# generated register map
File version: 1.0
Registers are 32-bit, access not given, no defined reset value unless marked. A register's access mark holds for its fields unless they carry their own. Offsets are from the block's base; lines under a group give offsets from that group; [hi:lo] are bit positions; {n}, {i} and the like mark numbered series; 'fields as' and 'values as' point back to an identical list; <NAME> marks a mode.

## Memory map
0x60047000 ieee802154
0x60049000 coex

## ieee802154
Base 0x60047000
0x00 command
  [7:0] opcode
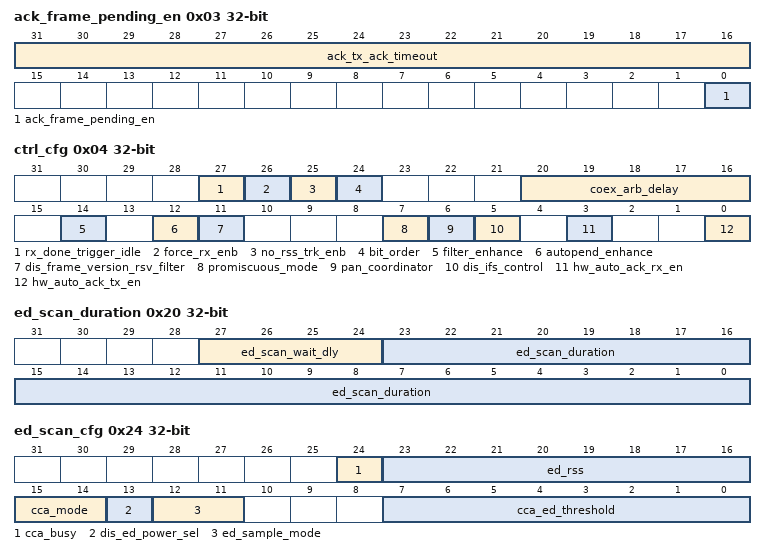
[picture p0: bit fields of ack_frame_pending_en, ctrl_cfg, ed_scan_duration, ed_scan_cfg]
0x03 ack_frame_pending_en
  [31:16] ack_tx_ack_timeout, [0] ack_frame_pending_en
0x04 ctrl_cfg
  [27] rx_done_trigger_idle, [26] force_rx_enb, [25] no_rss_trk_enb, [24] bit_order, [20:16] coex_arb_delay, [14] filter_enhance, [12] autopend_enhance, [11] dis_frame_version_rsv_filter, [7] promiscuous_mode, [6] pan_coordinator, [5] dis_ifs_control, [3] hw_auto_ack_rx_en, [0] hw_auto_ack_tx_en
0x08 short_addr
  [15:0] mac_short_addr
0x0C pan_id
  [15:0] mac_pan_id
0x10 extend_addr0
  [31:0] mac_extend_addr0
0x14 extend_addr1
  [31:0] mac_extend_addr1
0x18 channel
  [6:0] hop
0x1C tx_power
  [3:0] tx_power
0x20 ed_scan_duration
  [27:24] ed_scan_wait_dly, [23:0] ed_scan_duration
0x24 ed_scan_cfg
  [24] cca_busy, [23:16] ed_rss, [15:14] cca_mode, [13] dis_ed_power_sel, [12:11] ed_sample_mode, [7:0] cca_ed_threshold
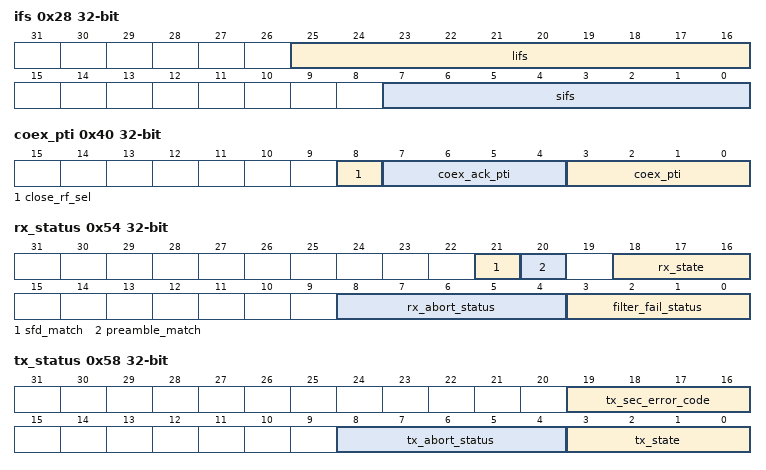
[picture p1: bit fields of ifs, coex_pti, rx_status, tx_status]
0x28 ifs
  [25:16] lifs, [7:0] sifs
0x2C ack_timeout
  [15:0] ack_timeout
0x30 event_en
  [12:0] event_en
0x34 event_status
  [12:0] event_status
0x38 rx_abort_intr_ctrl
  [30:0] rx_abort_intr_ctrl
0x40 coex_pti
  [8] close_rf_sel, [7:4] coex_ack_pti, [3:0] coex_pti
0x44 core_dummy_data
0x48 tx_abort_interrupt_control
  [30:0] tx_abort_interrupt_control
0x54 rx_status
  [21] sfd_match, [20] preamble_match, [18:16] rx_state, [8:4] rx_abort_status, [3:0] filter_fail_status
0x58 tx_status
  [19:16] tx_sec_error_code, [8:4] tx_abort_status, [3:0] tx_state
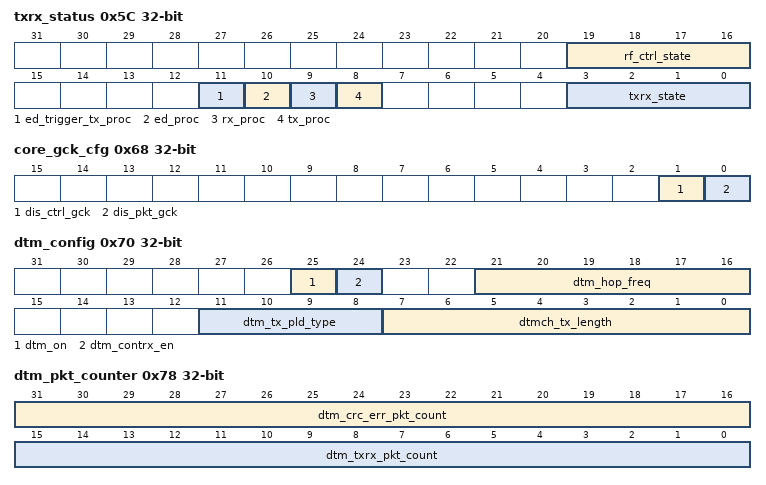
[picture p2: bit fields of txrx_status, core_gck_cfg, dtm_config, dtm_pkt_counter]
0x5C txrx_status
  [19:16] rf_ctrl_state, [11] ed_trigger_tx_proc, [10] ed_proc, [9] rx_proc, [8] tx_proc, [3:0] txrx_state
0x60 tx_ccm_schedule_status
  [30:0] tx_ccm_schedule_status
0x68 core_gck_cfg
  [1] dis_ctrl_gck, [0] dis_pkt_gck
0x6C test_control
  [0] wrong_crc
0x70 dtm_config
  [25] dtm_on, [24] dtm_contrx_en, [21:16] dtm_hop_freq, [11:8] dtm_tx_pld_type, [7:0] dtmch_tx_length
0x74 dtm_tx_pkt_config
  [15:0] dtm_tx_pkt_threshold
0x78 dtm_pkt_counter
  [31:16] dtm_crc_err_pkt_count, [15:0] dtm_txrx_pkt_count
0x7C rx_length
  [6:0] rx_length
0x80 time0_threshold
  [31:0] timer0_threshold
0x84 time0_value
  [31:0] timer0_value
0x88 time1_threshold
  [31:0] timer1_threshold
0x8C time1_value
  [31:0] timer1_value
0x90 clk_counter_match_val
  [15:0] clk_count_match_val
0x94 clk_counter
  [15:0] clk_625us_cnt
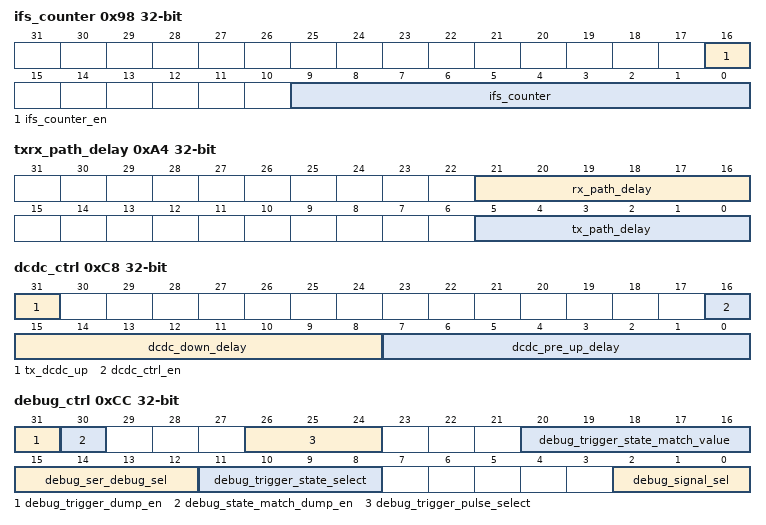
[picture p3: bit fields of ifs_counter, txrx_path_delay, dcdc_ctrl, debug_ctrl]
0x98 ifs_counter
  [16] ifs_counter_en, [9:0] ifs_counter
0xA0 sfd_wait_symbol
  [3:0] sfd_wait_symbol_num
0xA4 txrx_path_delay
  [21:16] rx_path_delay, [5:0] tx_path_delay
0xA8 bb_clk
  [4:0] bb_clk_freq_minus_1
0xAC paon_delay
  [9:0] paon_delay
0xB0 txon_delay
  [9:0] txon_delay
0xB4 txen_stop_delay
  [5:0] txen_stop_dly
0xB8 txoff_delay
  [5:0] txoff_delay
0xBC rxon_delay
  [10:0] rxon_delay
0xC0 txrx_switch_delay
  [9:0] txrx_switch_delay
0xC4 cont_rx_delay
  [5:0] cont_rx_delay
0xC8 dcdc_ctrl
  [31] tx_dcdc_up, [16] dcdc_ctrl_en, [15:8] dcdc_down_delay, [7:0] dcdc_pre_up_delay
0xCC debug_ctrl
  [31] debug_trigger_dump_en, [30] debug_state_match_dump_en, [26:24] debug_trigger_pulse_select, [20:16] debug_trigger_state_match_value, [15:12] debug_ser_debug_sel, [11:8] debug_trigger_state_select, [2:0] debug_signal_sel
0xD0 txdma_addr
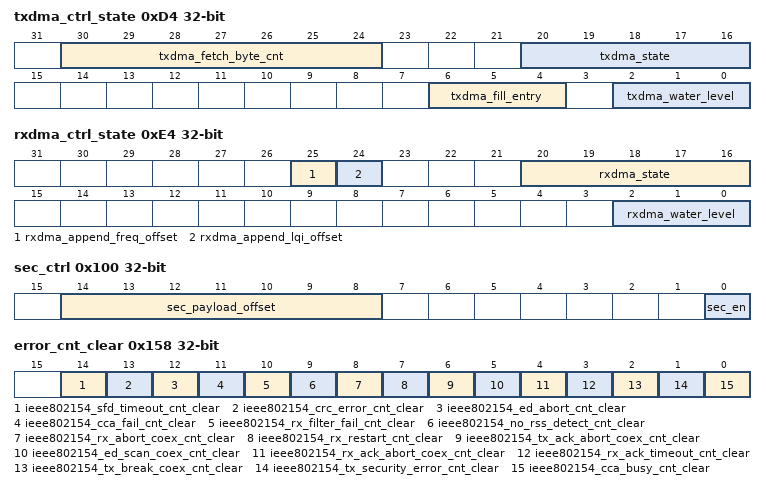
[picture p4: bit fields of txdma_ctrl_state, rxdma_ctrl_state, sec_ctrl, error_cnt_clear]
0xD4 txdma_ctrl_state
  [30:24] txdma_fetch_byte_cnt, [20:16] txdma_state, [6:4] txdma_fill_entry, [2:0] txdma_water_level
0xD8 txdma_err
  [3:0] txdma_err
0xE0 rxdma_addr
0xE4 rxdma_ctrl_state
  [25] rxdma_append_freq_offset, [24] rxdma_append_lqi_offset, [20:16] rxdma_state, [2:0] rxdma_water_level
0xE8 rxdma_err
  [3:0] rxdma_err
0xF0 dma_gck_cfg
  [0] dma_gck_cfg
0xF4 dma_dummy
  [31:0] dma_dummy_data
0x100 sec_ctrl
  [14:8] sec_payload_offset, [0] sec_en
0x108 sec_extend_address0
0x10C sec_extend_address1
{0x110+4i} sec_key{i} (i=0..3)
0x120 sfd_timeout_cnt
  [15:0] sfd_timeout_cnt
0x124 crc_error_cnt
  [15:0] crc_error_cnt
0x128 ed_abort_cnt
  [15:0] ed_abort_cnt
0x12C cca_fail_cnt
  [15:0] cca_fail_cnt
0x130 rx_filter_fail_cnt
  [15:0] rx_filter_fail_cnt
0x134 no_rss_detect_cnt
  [15:0] no_rss_detect_cnt
0x138 rx_abort_coex_cnt
  [15:0] rx_abort_coex_cnt
0x13C rx_restart_cnt
  [15:0] rx_restart_cnt
0x140 tx_ack_abort_coex_cnt
  [15:0] tx_ack_abort_coex_cnt
0x144 ed_scan_coex_cnt
  [15:0] ed_scan_coex_cnt
0x148 rx_ack_abort_coex_cnt
  [15:0] rx_ack_abort_coex_cnt
0x14C rx_ack_timeout_cnt
  [15:0] rx_ack_timeout_cnt
0x150 tx_break_coex_cnt
  [15:0] tx_break_coex_cnt
0x154 tx_security_error_cnt
  [15:0] tx_security_error_cnt
0x158 error_cnt_clear
  [14] ieee802154_sfd_timeout_cnt_clear, [13] ieee802154_crc_error_cnt_clear, [12] ieee802154_ed_abort_cnt_clear, [11] ieee802154_cca_fail_cnt_clear, [10] ieee802154_rx_filter_fail_cnt_clear, [9] ieee802154_no_rss_detect_cnt_clear, [8] ieee802154_rx_abort_coex_cnt_clear, [7] ieee802154_rx_restart_cnt_clear, [6] ieee802154_tx_ack_abort_coex_cnt_clear, [5] ieee802154_ed_scan_coex_cnt_clear, [4] ieee802154_rx_ack_abort_coex_cnt_clear, [3] ieee802154_rx_ack_timeout_cnt_clear, [2] ieee802154_tx_break_coex_cnt_clear, [1] ieee802154_tx_security_error_cnt_clear, [0] ieee802154_cca_busy_cnt_clear
0x158 cca_busy_cnt
  [15:0] cca_busy_cnt

## coex
Base 0x60049000
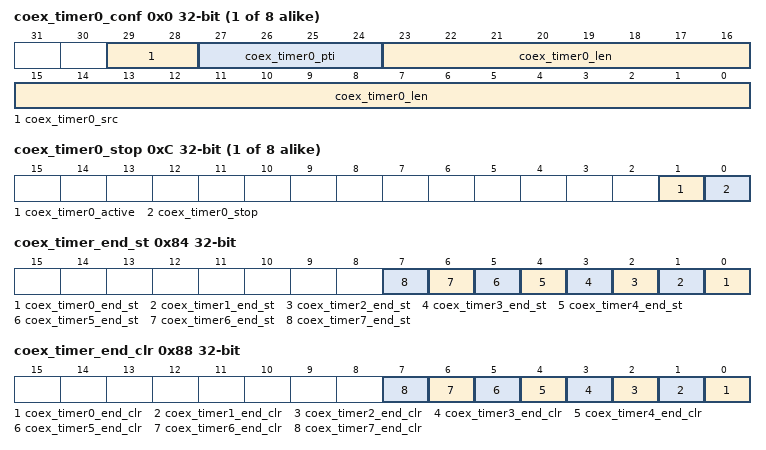
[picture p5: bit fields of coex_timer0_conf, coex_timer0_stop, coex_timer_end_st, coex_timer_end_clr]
{0x0+0x10*i} coex_timer{i}_conf (i=0..7)
  [29:28] coex_timer{i}_src, [27:24] coex_timer{i}_pti, [23:0] coex_timer{i}_len
{0x4+0x10*i} coex_timer{i}_conf1 (i=0..7)
  [23:0] coex_timer{i}_begin
{0x8+0x10*i} coex_timer{i}_start (i=0..7)
  [0] coex_timer{i}_start
{0xC+0x10*i} coex_timer{i}_stop (i=0..7)
  [1] coex_timer{i}_active, [0] coex_timer{i}_stop
0x80 coex_timer
  [23:0] coex_ctimer
0x84 coex_timer_end_st
  [n] coex_timer{n}_end_st (n=0..7)
0x88 coex_timer_end_clr
  [n] coex_timer{n}_end_clr (n=0..7)
0x8C coex_int_ena
  [0] coex_timer_end_int_ena
0x90 coex_int_raw
  [0] coex_timer_end_int_raw
0x94 coex_int_st
  [0] coex_timer_end_int_st
0x98 coex_int_clr
  [0] coex_timer_end_int_clr
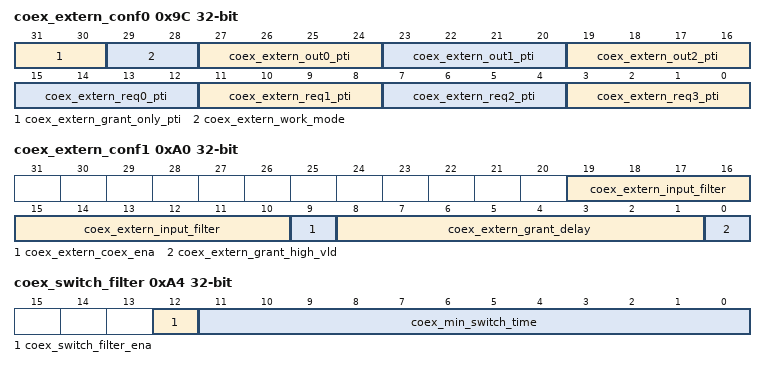
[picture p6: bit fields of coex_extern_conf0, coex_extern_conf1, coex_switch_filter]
0x9C coex_extern_conf0
  [31:30] coex_extern_grant_only_pti, [29:28] coex_extern_work_mode, [27:24] coex_extern_out0_pti, [23:20] coex_extern_out1_pti, [19:16] coex_extern_out2_pti, [15-4n:12-4n] coex_extern_req{n}_pti (n=0..3)
0xA0 coex_extern_conf1
  [19:10] coex_extern_input_filter, [9] coex_extern_coex_ena, [8:1] coex_extern_grant_delay, [0] coex_extern_grant_high_vld
0xA4 coex_switch_filter
  [12] coex_switch_filter_ena, [11:0] coex_min_switch_time
0xA8 coex_clk_conf
  [0] coex_clk_en
{0xAC+4i} coex_src{i}_disbale (i=0..2)
  [0] coex_src{i}_dis
{0xB8+4i} ocex_src{i}_select (i=0..2)
  [1:0] coex_src{i}_sel
0xC4 coex_date
  [27:0] coex_date
